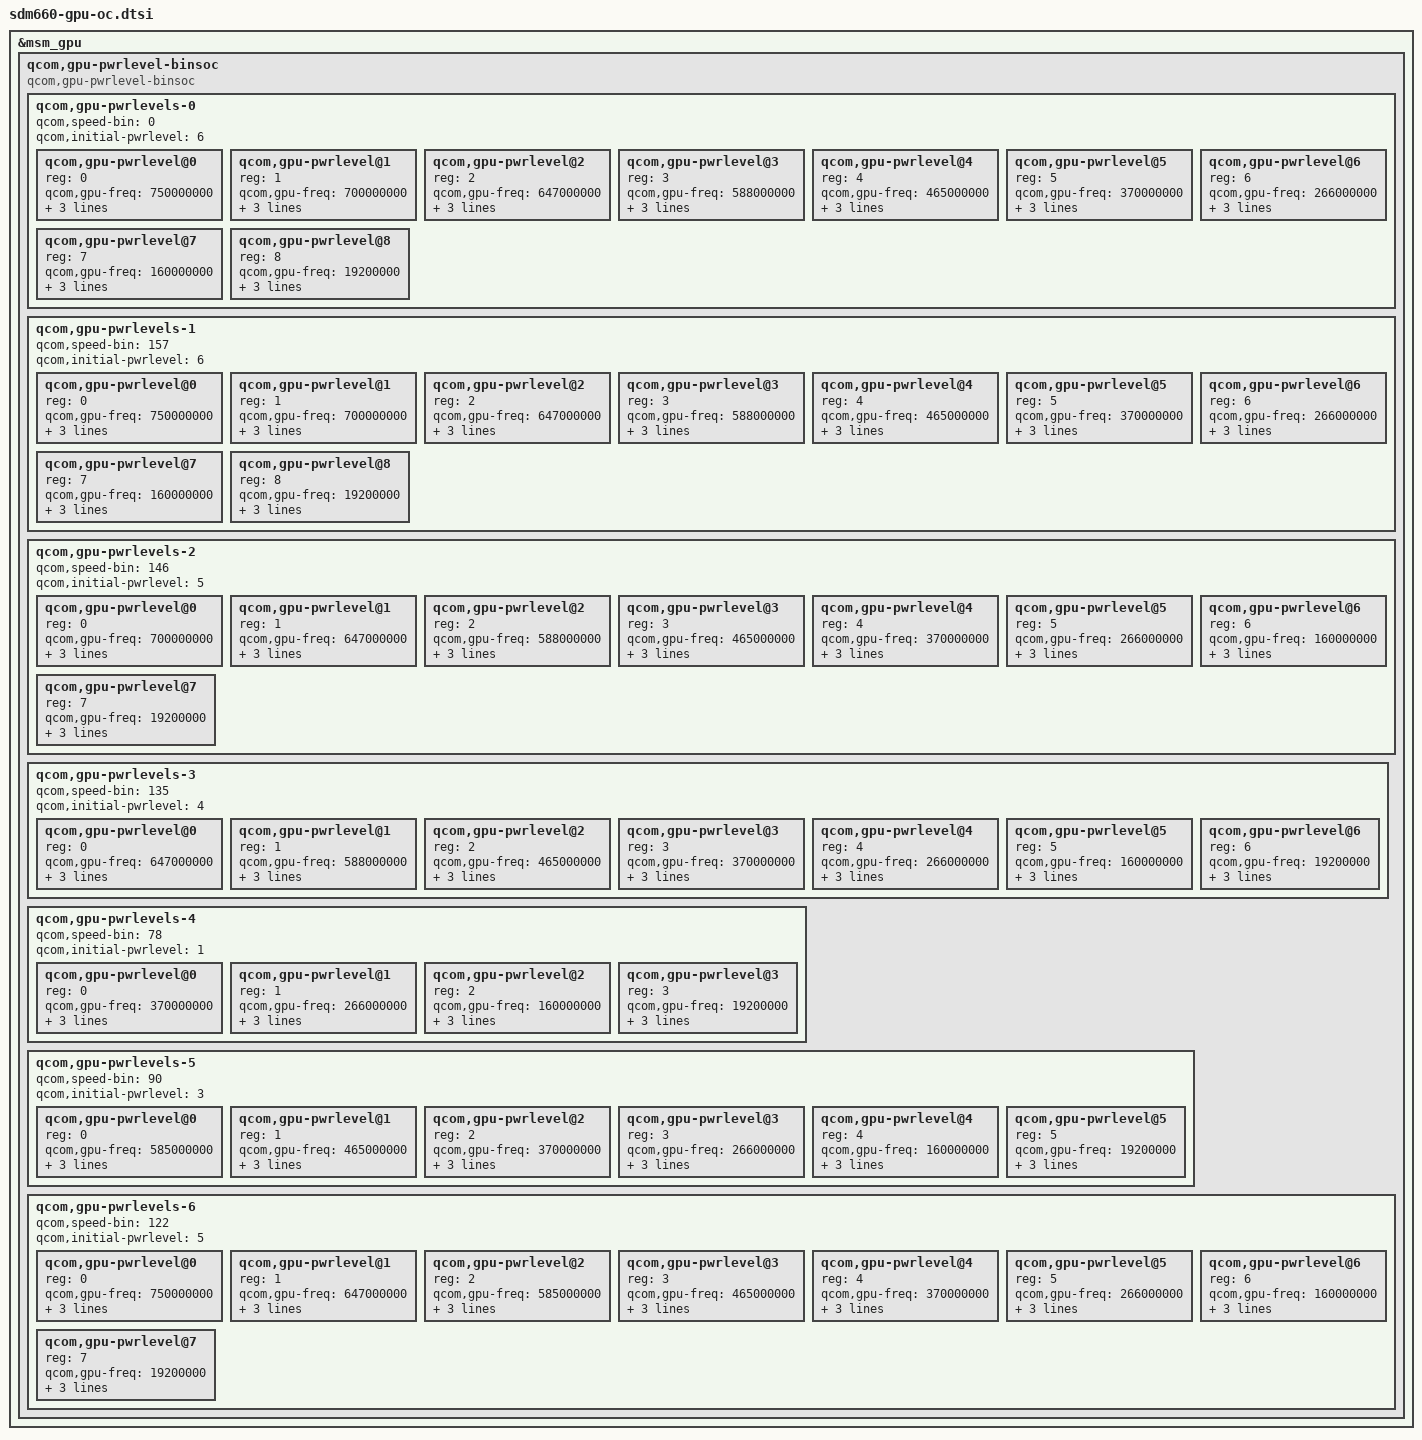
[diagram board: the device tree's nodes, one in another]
&msm_gpu {
	qcom,gpu-pwrlevel-binsoc {
		#address-cells = <1>;
		#size-cells = <0>;

		compatible="qcom,gpu-pwrlevel-binsoc";

		qcom,gpu-pwrlevels-0 {
			#address-cells = <1>;
			#size-cells = <0>;

			qcom,speed-bin = <0>;

			qcom,initial-pwrlevel = <6>;

			/* TURBO */
			qcom,gpu-pwrlevel@0 {
				reg = <0>;
				qcom,gpu-freq = <750000000>;
				qcom,bus-freq = <13>;
				qcom,bus-min = <12>;
				qcom,bus-max = <13>;
			};

			/* TURBO */
			qcom,gpu-pwrlevel@1 {
				reg = <1>;
				qcom,gpu-freq = <700000000>;
				qcom,bus-freq = <11>;
				qcom,bus-min = <11>;
				qcom,bus-max = <13>;
			};

			/* NOM_L1 */
			qcom,gpu-pwrlevel@2 {
				reg = <2>;
				qcom,gpu-freq = <647000000>;
				qcom,bus-freq = <11>;
				qcom,bus-min = <10>;
				qcom,bus-max = <12>;
			};

			/* NOM */
			qcom,gpu-pwrlevel@3 {
				reg = <3>;
				qcom,gpu-freq = <588000000>;
				qcom,bus-freq = <10>;
				qcom,bus-min = <9>;
				qcom,bus-max = <12>;
			};

			/* SVS_L1 */
			qcom,gpu-pwrlevel@4 {
				reg = <4>;
				qcom,gpu-freq = <465000000>;
				qcom,bus-freq = <9>;
				qcom,bus-min = <8>;
				qcom,bus-max = <11>;
			};

			/* SVS */
			qcom,gpu-pwrlevel@5 {
				reg = <5>;
				qcom,gpu-freq = <370000000>;
				qcom,bus-freq = <8>;
				qcom,bus-min = <6>;
				qcom,bus-max = <9>;
			};

			/* Low SVS */
			qcom,gpu-pwrlevel@6 {
				reg = <6>;
				qcom,gpu-freq = <266000000>;
				qcom,bus-freq = <3>;
				qcom,bus-min = <3>;
				qcom,bus-max = <6>;
			};

			/* Min SVS */
			qcom,gpu-pwrlevel@7 {
				reg = <7>;
				qcom,gpu-freq = <160000000>;
				qcom,bus-freq = <3>;
				qcom,bus-min = <3>;
				qcom,bus-max = <5>;
			};

			/* XO */
			qcom,gpu-pwrlevel@8 {
				reg = <8>;
				qcom,gpu-freq = <19200000>;
				qcom,bus-freq = <0>;
				qcom,bus-min = <0>;
				qcom,bus-max = <0>;
			};
		};

		qcom,gpu-pwrlevels-1 {
			#address-cells = <1>;
			#size-cells = <0>;

			qcom,speed-bin = <157>;

			qcom,initial-pwrlevel = <6>;

			/* TURBO */
			qcom,gpu-pwrlevel@0 {
				reg = <0>;
				qcom,gpu-freq = <750000000>;
				qcom,bus-freq = <13>;
				qcom,bus-min = <12>;
				qcom,bus-max = <13>;
			};

			/* TURBO */
			qcom,gpu-pwrlevel@1 {
				reg = <1>;
				qcom,gpu-freq = <700000000>;
				qcom,bus-freq = <11>;
				qcom,bus-min = <11>;
				qcom,bus-max = <13>;
			};

			/* NOM_L1 */
			qcom,gpu-pwrlevel@2 {
				reg = <2>;
				qcom,gpu-freq = <647000000>;
				qcom,bus-freq = <11>;
				qcom,bus-min = <10>;
				qcom,bus-max = <12>;
			};

			/* NOM */
			qcom,gpu-pwrlevel@3 {
				reg = <3>;
				qcom,gpu-freq = <588000000>;
				qcom,bus-freq = <10>;
				qcom,bus-min = <9>;
				qcom,bus-max = <12>;
			};

			/* SVS_L1 */
			qcom,gpu-pwrlevel@4 {
				reg = <4>;
				qcom,gpu-freq = <465000000>;
				qcom,bus-freq = <9>;
				qcom,bus-min = <8>;
				qcom,bus-max = <11>;
			};

			/* SVS */
			qcom,gpu-pwrlevel@5 {
				reg = <5>;
				qcom,gpu-freq = <370000000>;
				qcom,bus-freq = <8>;
				qcom,bus-min = <6>;
				qcom,bus-max = <9>;
			};

			/* Low SVS */
			qcom,gpu-pwrlevel@6 {
				reg = <6>;
				qcom,gpu-freq = <266000000>;
				qcom,bus-freq = <3>;
				qcom,bus-min = <3>;
				qcom,bus-max = <6>;
			};

			/* Min SVS */
			qcom,gpu-pwrlevel@7 {
				reg = <7>;
				qcom,gpu-freq = <160000000>;
				qcom,bus-freq = <3>;
				qcom,bus-min = <3>;
				qcom,bus-max = <5>;
			};

			/* XO */
			qcom,gpu-pwrlevel@8 {
				reg = <8>;
				qcom,gpu-freq = <19200000>;
				qcom,bus-freq = <0>;
				qcom,bus-min = <0>;
				qcom,bus-max = <0>;
			};
		};

		qcom,gpu-pwrlevels-2 {
			#address-cells = <1>;
			#size-cells = <0>;

			qcom,speed-bin = <146>;

			qcom,initial-pwrlevel = <5>;

			/* TURBO */
			qcom,gpu-pwrlevel@0 {
				reg = <0>;
				qcom,gpu-freq = <700000000>;
				qcom,bus-freq = <13>;
				qcom,bus-min = <12>;
				qcom,bus-max = <13>;
			};

			/* NOM_L1 */
			qcom,gpu-pwrlevel@1 {
				reg = <1>;
				qcom,gpu-freq = <647000000>;
				qcom,bus-freq = <11>;
				qcom,bus-min = <10>;
				qcom,bus-max = <12>;
			};

			/* NOM */
			qcom,gpu-pwrlevel@2 {
				reg = <2>;
				qcom,gpu-freq = <588000000>;
				qcom,bus-freq = <10>;
				qcom,bus-min = <9>;
				qcom,bus-max = <12>;
			};

			/* SVS_L1 */
			qcom,gpu-pwrlevel@3 {
				reg = <3>;
				qcom,gpu-freq = <465000000>;
				qcom,bus-freq = <9>;
				qcom,bus-min = <8>;
				qcom,bus-max = <11>;
			};

			/* SVS */
			qcom,gpu-pwrlevel@4 {
				reg = <4>;
				qcom,gpu-freq = <370000000>;
				qcom,bus-freq = <8>;
				qcom,bus-min = <6>;
				qcom,bus-max = <9>;
			};

			/* Low SVS */
			qcom,gpu-pwrlevel@5 {
				reg = <5>;
				qcom,gpu-freq = <266000000>;
				qcom,bus-freq = <3>;
				qcom,bus-min = <3>;
				qcom,bus-max = <6>;
			};

			/* Min SVS */
			qcom,gpu-pwrlevel@6 {
				reg = <6>;
				qcom,gpu-freq = <160000000>;
				qcom,bus-freq = <3>;
				qcom,bus-min = <3>;
				qcom,bus-max = <5>;
			};

			/* XO */
			qcom,gpu-pwrlevel@7 {
				reg = <7>;
				qcom,gpu-freq = <19200000>;
				qcom,bus-freq = <0>;
				qcom,bus-min = <0>;
				qcom,bus-max = <0>;
			};
		};

		qcom,gpu-pwrlevels-3 {
			#address-cells = <1>;
			#size-cells = <0>;

			qcom,speed-bin = <135>;

			qcom,initial-pwrlevel = <4>;

			/* NOM_L1 */
			qcom,gpu-pwrlevel@0 {
				reg = <0>;
				qcom,gpu-freq = <647000000>;
				qcom,bus-freq = <13>;
				qcom,bus-min = <12>;
				qcom,bus-max = <13>;
			};

			/* NOM */
			qcom,gpu-pwrlevel@1 {
				reg = <1>;
				qcom,gpu-freq = <588000000>;
				qcom,bus-freq = <10>;
				qcom,bus-min = <9>;
				qcom,bus-max = <12>;
			};

			/* SVS_L1 */
			qcom,gpu-pwrlevel@2 {
				reg = <2>;
				qcom,gpu-freq = <465000000>;
				qcom,bus-freq = <9>;
				qcom,bus-min = <8>;
				qcom,bus-max = <11>;
			};

			/* SVS */
			qcom,gpu-pwrlevel@3 {
				reg = <3>;
				qcom,gpu-freq = <370000000>;
				qcom,bus-freq = <8>;
				qcom,bus-min = <6>;
				qcom,bus-max = <9>;
			};

			/* Low SVS */
			qcom,gpu-pwrlevel@4 {
				reg = <4>;
				qcom,gpu-freq = <266000000>;
				qcom,bus-freq = <3>;
				qcom,bus-min = <3>;
				qcom,bus-max = <6>;
			};

			/* Min SVS */
			qcom,gpu-pwrlevel@5 {
				reg = <5>;
				qcom,gpu-freq = <160000000>;
				qcom,bus-freq = <3>;
				qcom,bus-min = <3>;
				qcom,bus-max = <5>;
			};

			/* XO */
			qcom,gpu-pwrlevel@6 {
				reg = <6>;
				qcom,gpu-freq = <19200000>;
				qcom,bus-freq = <0>;
				qcom,bus-min = <0>;
				qcom,bus-max = <0>;
			};
		};

		qcom,gpu-pwrlevels-4 {
			#address-cells = <1>;
			#size-cells = <0>;

			qcom,speed-bin = <78>;

			qcom,initial-pwrlevel = <1>;

			/* SVS */
			qcom,gpu-pwrlevel@0 {
				reg = <0>;
				qcom,gpu-freq = <370000000>;
				qcom,bus-freq = <8>;
				qcom,bus-min = <6>;
				qcom,bus-max = <11>;
			};

			/* Low SVS */
			qcom,gpu-pwrlevel@1 {
				reg = <1>;
				qcom,gpu-freq = <266000000>;
				qcom,bus-freq = <3>;
				qcom,bus-min = <3>;
				qcom,bus-max = <6>;
			};

			/* Min SVS */
			qcom,gpu-pwrlevel@2 {
				reg = <2>;
				qcom,gpu-freq = <160000000>;
				qcom,bus-freq = <3>;
				qcom,bus-min = <3>;
				qcom,bus-max = <5>;
			};

			/* XO */
			qcom,gpu-pwrlevel@3 {
				reg = <3>;
				qcom,gpu-freq = <19200000>;
				qcom,bus-freq = <0>;
				qcom,bus-min = <0>;
				qcom,bus-max = <0>;
			};
		};

		qcom,gpu-pwrlevels-5 {
			#address-cells = <1>;
			#size-cells = <0>;

			qcom,speed-bin = <90>;

			qcom,initial-pwrlevel = <3>;

			/* NOM */
			qcom,gpu-pwrlevel@0 {
				reg = <0>;
				qcom,gpu-freq = <585000000>;
				qcom,bus-freq = <12>;
				qcom,bus-min = <11>;
				qcom,bus-max = <12>;
			};
			
			/* SVS_L1 */
			qcom,gpu-pwrlevel@1 {
				reg = <1>;
				qcom,gpu-freq = <465000000>;
				qcom,bus-freq = <9>;
				qcom,bus-min = <8>;
				qcom,bus-max = <11>;
			};

			/* SVS */
			qcom,gpu-pwrlevel@2 {
				reg = <2>;
				qcom,gpu-freq = <370000000>;
				qcom,bus-freq = <8>;
				qcom,bus-min = <6>;
				qcom,bus-max = <11>;
			};

			/* Low SVS */
			qcom,gpu-pwrlevel@3 {
				reg = <3>;
				qcom,gpu-freq = <266000000>;
				qcom,bus-freq = <3>;
				qcom,bus-min = <3>;
				qcom,bus-max = <6>;
			};

			/* Min SVS */
			qcom,gpu-pwrlevel@4 {
				reg = <4>;
				qcom,gpu-freq = <160000000>;
				qcom,bus-freq = <3>;
				qcom,bus-min = <3>;
				qcom,bus-max = <5>;
			};

			/* XO */
			qcom,gpu-pwrlevel@5 {
				reg = <5>;
				qcom,gpu-freq = <19200000>;
				qcom,bus-freq = <0>;
				qcom,bus-min = <0>;
				qcom,bus-max = <0>;
			};
		};

		qcom,gpu-pwrlevels-6 {
			#address-cells = <1>;
			#size-cells = <0>;

			qcom,speed-bin = <122>;

			qcom,initial-pwrlevel = <5>;

			/* TURBO */
			qcom,gpu-pwrlevel@0 {
				reg = <0>;
				qcom,gpu-freq = <750000000>;
				qcom,bus-freq = <12>;
				qcom,bus-min = <11>;
				qcom,bus-max = <12>;
			};

			/* NOM_L1 */
			qcom,gpu-pwrlevel@1 {
				reg = <1>;
				qcom,gpu-freq = <647000000>;
				qcom,bus-freq = <12>;
				qcom,bus-min = <11>;
				qcom,bus-max = <12>;
			};

			/* NOM */
			qcom,gpu-pwrlevel@2 {
				reg = <2>;
				qcom,gpu-freq = <585000000>;
				qcom,bus-freq = <12>;
				qcom,bus-min = <11>;
				qcom,bus-max = <12>;
			};

			/* SVS_L1 */
			qcom,gpu-pwrlevel@3 {
				reg = <3>;
				qcom,gpu-freq = <465000000>;
				qcom,bus-freq = <9>;
				qcom,bus-min = <8>;
				qcom,bus-max = <11>;
			};

			/* SVS */
			qcom,gpu-pwrlevel@4 {
				reg = <4>;
				qcom,gpu-freq = <370000000>;
				qcom,bus-freq = <8>;
				qcom,bus-min = <6>;
				qcom,bus-max = <9>;
			};

			/* Low SVS */
			qcom,gpu-pwrlevel@5 {
				reg = <5>;
				qcom,gpu-freq = <266000000>;
				qcom,bus-freq = <3>;
				qcom,bus-min = <3>;
				qcom,bus-max = <6>;
			};

			/* Min SVS */
			qcom,gpu-pwrlevel@6 {
				reg = <6>;
				qcom,gpu-freq = <160000000>;
				qcom,bus-freq = <3>;
				qcom,bus-min = <3>;
				qcom,bus-max = <5>;
			};

			/* XO */
			qcom,gpu-pwrlevel@7 {
				reg = <7>;
				qcom,gpu-freq = <19200000>;
				qcom,bus-freq = <0>;
				qcom,bus-min = <0>;
				qcom,bus-max = <0>;
			};
		};
	};
};
